AUTOSAR XML (schema 00044)
package /ComponentTypes
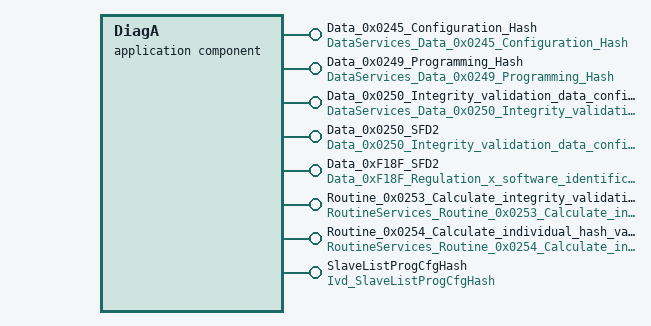
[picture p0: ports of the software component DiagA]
  application sw component type DiagA
    8 x provide port:
      Data_0x0245_Configuration_Hash: provided-com-specs=[{operation=ConditionCheckRead, queue-length=1}, {operation=ReadData, queue-length=1}], provided-interface=DataServices_Data_0x0245_Configuration_Hash
      Data_0x0249_Programming_Hash: provided-com-specs=[{operation=ConditionCheckRead, queue-length=1}, {operation=ReadData, queue-length=1}], provided-interface=DataServices_Data_0x0249_Programming_Hash
      Data_0x0250_Integrity_validation_data_configuration_list: provided-interface=DataServices_Data_0x0250_Integrity_validation_data_configuration_list
        provided-com-specs:
          operation=ConditionCheckRead, queue-length=1
          operation=ReadData, queue-length=1
          operation=ReadDataLength, queue-length=1
          operation=WriteData, queue-length=1
      Data_0x0250_SFD2: provided-interface=Data_0x0250_Integrity_validation_data_configuration_list_SFD2
        provided-com-specs:
          operation=ConditionCheckRead, queue-length=1
          operation=ReadData, queue-length=1
          operation=ReadDataLength, queue-length=1
          operation=WriteData, queue-length=1
      Data_0xF18F_SFD2: provided-interface=Data_0xF18F_Regulation_x_software_identification_numbers_SFD2
        provided-com-specs:
          operation=ConditionCheckRead, queue-length=1
          operation=ReadData, queue-length=1
          operation=ReadDataLength, queue-length=1
          operation=WriteData, queue-length=1
      Routine_0x0253_Calculate_integrity_validation_data_Start: server-com-spec{operation=Start, queue-length=1}, provided-interface=RoutineServices_Routine_0x0253_Calculate_integrity_validation_data_Start
      Routine_0x0254_Calculate_individual_hash_value_Start: server-com-spec{operation=Start, queue-length=1}, provided-interface=RoutineServices_Routine_0x0254_Calculate_individual_hash_value_Start
      SlaveListProgCfgHash: provided-com-specs=[{operation=Data, queue-length=1}, {operation=Hash, queue-length=1}], provided-interface=Ivd_SlaveListProgCfgHash
    behavior DiagA_InternalBehavior
      20 x operation invoked event:
        OIT_Data_0x0245_Configuration_Hash_ConditionCheckRead_Data_0x0245_Configuration_Hash_ConditionCheckRead: start-on-event=Data_0x0245_Configuration_Hash_ConditionCheckRead, operation=Data_0x0245_Configuration_Hash.ConditionCheckRead
        OIT_Data_0x0245_Configuration_Hash_ReadData_Data_0x0245_Configuration_Hash_ReadData: start-on-event=Data_0x0245_Configuration_Hash_ReadData, operation=Data_0x0245_Configuration_Hash.ReadData
        OIT_Data_0x0249_Programming_Hash_ConditionCheckRead_Data_0x0249_Programming_Hash_ConditionCheckRead: start-on-event=Data_0x0249_Programming_Hash_ConditionCheckRead, operation=Data_0x0249_Programming_Hash.ConditionCheckRead
        OIT_Data_0x0249_Programming_Hash_ReadData_Data_0x0249_Programming_Hash_ReadData: start-on-event=Data_0x0249_Programming_Hash_ReadData, operation=Data_0x0249_Programming_Hash.ReadData
        OIT_Data_0x0250_Integrity_validation_data_configuration_list_ConditionCheckRead_Data_0x0250_Integrity_validation_data_coF4607225: start-on-event=Data_0x0250_Integrity_validation_data_configuration_list_ConditionCheckRead, operation=Data_0x0250_Integrity_validation_data_configuration_list.ConditionCheckRead
        OIT_Data_0x0250_Integrity_validation_data_configuration_list_ReadData_Data_0x0250_Integrity_validation_data_configuratio55BBACF9: start-on-event=Data_0x0250_Integrity_validation_data_configuration_list_ReadData, operation=Data_0x0250_Integrity_validation_data_configuration_list.ReadData
        OIT_Data_0x0250_Integrity_validation_data_configuration_list_ReadDataLength_Data_0x0250_Integrity_validation_data_configA7BA6501: start-on-event=Data_0x0250_Integrity_validation_data_configuration_list_ReadDataLength, operation=Data_0x0250_Integrity_validation_data_configuration_list.ReadDataLength
        OIT_Data_0x0250_SFD2_ConditionCheckRead_Data_0x0250_SFD2_ConditionCheckRead: start-on-event=Data_0x0250_Integrity_validation_data_configuration_list_SFD2_ConditionCheckRead, operation=Data_0x0250_SFD2.ConditionCheckRead
        OIT_Data_0x0250_SFD2_ReadData_Data_0x0250_SFD2_ReadData: start-on-event=Data_0x0250_Integrity_validation_data_configuration_list_SFD2_ReadData, operation=Data_0x0250_SFD2.ReadData
        OIT_Data_0x0250_SFD2_ReadDataLength_Data_0x0250_SFD2_ReadDataLength: start-on-event=Data_0x0250_Integrity_validation_data_configuration_list_SFD2_ReadDataLength, operation=Data_0x0250_SFD2.ReadDataLength
        OIT_Data_0x0250_SFD2_WriteData_Data_0x0250_SFD2_WriteData: start-on-event=Data_0x0250_Integrity_validation_data_configuration_list_SFD2_WriteData, operation=Data_0x0250_SFD2.WriteData
        OIT_Data_0x0250_Integrity_validation_data_configuration_list_WriteData_Data_0x0250_Integrity_validation_data_configurati9AFB355F: start-on-event=Data_0x0250_Integrity_validation_data_configuration_list_WriteData, operation=Data_0x0250_Integrity_validation_data_configuration_list.WriteData
        OIT_Data_0xF18F_SFD2_ConditionCheckRead_Data_0xF18F_SFD2_ConditionCheckRead: start-on-event=Data_0xF18F_Regulation_x_software_identification_numbers_SFD2_ConditionCheckRead, operation=Data_0xF18F_SFD2.ConditionCheckRead
        OIT_Data_0xF18F_SFD2_ReadData_Data_0xF18F_SFD2_ReadData: start-on-event=Data_0xF18F_Regulation_x_software_identification_numbers_SFD2_ReadData, operation=Data_0xF18F_SFD2.ReadData
        OIT_Data_0xF18F_SFD2_ReadDataLength_Data_0xF18F_SFD2_ReadDataLength: start-on-event=Data_0xF18F_Regulation_x_software_identification_numbers_SFD2_ReadDataLength, operation=Data_0xF18F_SFD2.ReadDataLength
        OIT_Data_0xF18F_SFD2_WriteData_Data_0xF18F_SFD2_WriteData: start-on-event=Data_0xF18F_Regulation_x_software_identification_numbers_SFD2_WriteData, operation=Data_0xF18F_SFD2.WriteData
        OIT_Routine_0x0253_Calculate_integrity_validation_data_Start_Routine_0x0253_Calculate_integrity_validation_data_Start_Start: start-on-event=Routine_0x0253_Calculate_integrity_validation_data_Start, operation=Routine_0x0253_Calculate_integrity_validation_data_Start.Start
        OIT_Routine_0x0254_Calculate_individual_hash_value_Start_Routine_0x0254_Calculate_individual_hash_value_Start_Start: start-on-event=Routine_0x0254_Calculate_individual_hash_value_Start, operation=Routine_0x0254_Calculate_individual_hash_value_Start.Start
        OIT_SlaveListProgCfgHash_Data_SlaveListProgCfgHash_Data: start-on-event=SlaveListProgCfgHash_Data, operation=SlaveListProgCfgHash.Data
        OIT_SlaveListProgCfgHash_Hash_SlaveListProgCfgHash_Hash: start-on-event=SlaveListProgCfgHash_Hash, operation=SlaveListProgCfgHash.Hash
      20 x runnable:
        Data_0x0245_Configuration_Hash_ConditionCheckRead: symbol=Data0x0245_ConditionCheckRead
        Data_0x0245_Configuration_Hash_ReadData: symbol=Data0x0245_ReadData
        Data_0x0249_Programming_Hash_ConditionCheckRead: symbol=Data0x0249_ConditionCheckRead
        Data_0x0249_Programming_Hash_ReadData: symbol=Data0x0249_ReadData
        Data_0x0250_Integrity_validation_data_configuration_list_ConditionCheckRead: symbol=Data0x0250_ConditionCheckRead
        Data_0x0250_Integrity_validation_data_configuration_list_ReadData: symbol=Data0x0250_ReadData
        Data_0x0250_Integrity_validation_data_configuration_list_ReadDataLength: symbol=Data0x0250_ReadDataLength
        Data_0x0250_Integrity_validation_data_configuration_list_SFD2_ConditionCheckRead: symbol=Data0x0250Sfd2_ConditionCheckRead
        Data_0x0250_Integrity_validation_data_configuration_list_SFD2_ReadData: symbol=Data0x0250Sfd2_ReadData
        Data_0x0250_Integrity_validation_data_configuration_list_SFD2_ReadDataLength: symbol=Data0x0250Sfd2_ReadDataLength
        Data_0x0250_Integrity_validation_data_configuration_list_SFD2_WriteData: symbol=Data0x0250Sfd2_WriteData
        Data_0x0250_Integrity_validation_data_configuration_list_WriteData: symbol=Data0x0250_WriteData
        Data_0xF18F_Regulation_x_software_identification_numbers_SFD2_ConditionCheckRead: symbol=Data0xF18FSfd2_ConditionCheckRead
        Data_0xF18F_Regulation_x_software_identification_numbers_SFD2_ReadData: symbol=Data0xF18FSfd2_ReadData
        Data_0xF18F_Regulation_x_software_identification_numbers_SFD2_ReadDataLength: symbol=Data0xF18FSfd2_ReadDataLength
        Data_0xF18F_Regulation_x_software_identification_numbers_SFD2_WriteData: symbol=Data0xF18FSfd2_WriteData
        Routine_0x0253_Calculate_integrity_validation_data_Start: symbol=Routine0x0253_Start
        Routine_0x0254_Calculate_individual_hash_value_Start: symbol=Routine0x0254_Start
        SlaveListProgCfgHash_Data
        SlaveListProgCfgHash_Hash
  swc implementation DiagA_Implementation: vendor-id=75, behavior=DiagA_InternalBehavior
    code-descriptors:
      code Default: artifact-descriptors=autosar-engineering-object=category=SWSRC
    resource consumption ResourceConsumption
      memory section CODE: sw-addrmethod=CODE
      memory section CONST_UNSPECIFIED: alignment=UNSPECIFIED, sw-addrmethod=CONST
